# f28p65x_dev_cfg_regs register map
Vendor: Texas Instruments
Peripheral module from a debugger description file (folder C2000).
Address unit: 16 bits
Registers are 32-bit, read-write, no defined reset value unless marked. A register's access mark holds for its fields unless they carry their own. Offsets are as the file gives them; lines under a group give offsets from that group; [hi:lo] are bit positions; {n}, {i} and the like mark numbered series; 'fields as' and 'values as' point back to an identical list; <NAME> marks a mode.

## DEV_CFG_REGS — DEV CFG Registers
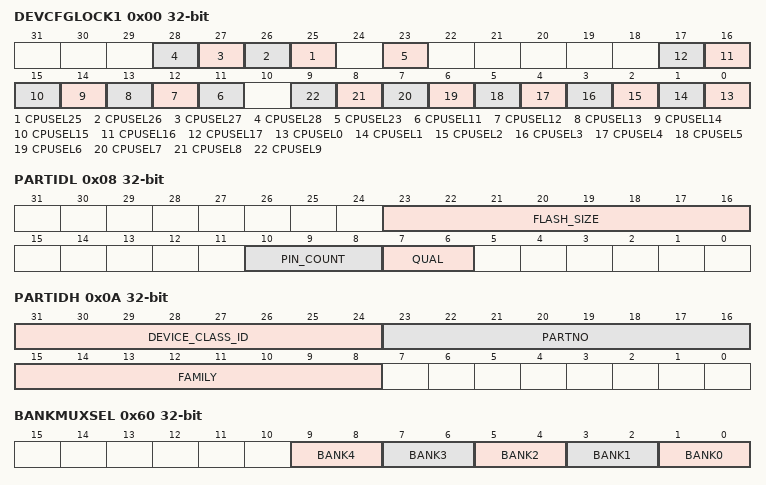
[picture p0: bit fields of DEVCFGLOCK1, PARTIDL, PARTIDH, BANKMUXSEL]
0x00 DEVCFGLOCK1 — Lock bit for CPUSELx registers
  [n] CPUSEL{n} (n=25..28) — Lock bit for CPUSEL{n} register
  [23] CPUSEL23 — Lock bit for CPUSEL23 register
  [n] CPUSEL{n} (n=11..17) — Lock bit for CPUSEL{n} register
  [n] CPUSEL{n} (n=0..9) — Lock bit for CPUSEL{n} register
0x02 DEVCFGLOCK2 — Lock bit for DEVCFG registers
  [2] BANKMUXSEL — Flash Bank Mux Select
0x08 PARTIDL — Lower 32-bit of Device PART Identification Number
  [23:16] FLASH_SIZE
  [10:8] PIN_COUNT — Device Pin Count
  [7:6] QUAL — Qualification Status
0x0A PARTIDH access per field — Upper 32-bit of Device PART Identification Number
  [31:24] DEVICE_CLASS_ID ro
  [23:16] PARTNO rw — Device part number
  [15:8] FAMILY rw — Device family
0x0C REVID — Device Revision Number
  [15:0] REVID — Device Revision ID. This is specific to the Device
0x10 DC0 access not given — Device Capability: Device Information
0x60 BANKMUXSEL — Flash Bank allocation to CPU. Internal note : This register is accessible (read-only) by CPU2, for devices with CPU2
  [2n+1:2n] BANK{n} (n=0..4) — Select Flash Bank Controller CPU for Read accesses
0x78 MCUCNF0 — MCU Configuration register for DC0.DUAL_CORE
  [0] DUAL_CORE — User Configurable Single Core vs Dual Core
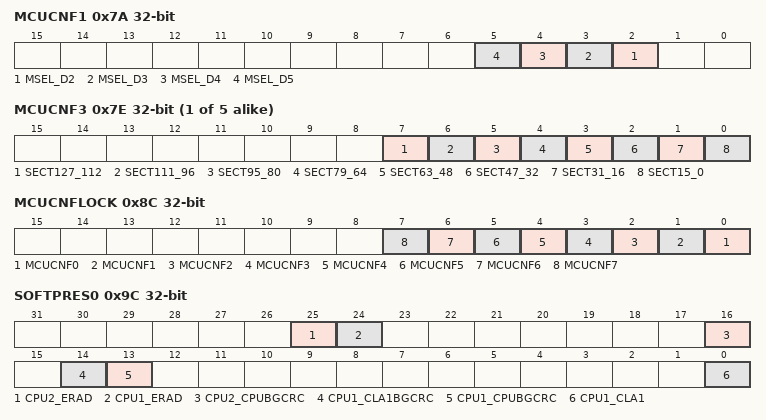
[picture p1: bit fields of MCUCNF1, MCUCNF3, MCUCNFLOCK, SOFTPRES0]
0x7A MCUCNF1 — MCU Configuration register for LockStep Feature on device
  [n] MSEL_D{n} (n=2..5) — Controller Select for MSEL_D{n}
0x7C MCUCNF2 — MCU Configuration register for EtherCAT
  [0] ETHERCAT
{0x78+2i} MCUCNF{i} (i=3..7) — MCU Configuration register for Flash Bank {i-2}
  [7] SECT127_112 — Flash sectors 127_112 present
  [6] SECT111_96 — Flash sectors 111_96 present
  [5] SECT95_80 — Flash sectors 95_80 present
  [4] SECT79_64 — Flash sectors 79_64 present
  [3] SECT63_48 — Flash sectors 63_48 present
  [2] SECT47_32 — Flash sectors 47_32 present
  [1] SECT31_16 — Flash sectors 31_16 present
  [0] SECT15_0 — Flash sectors 15_0 present
0x8C MCUCNFLOCK — Lock bit for MCUCNFx registers
  [n] MCUCNF{n} (n=0..7) — Lock bit for MCUCNF{n} register
0x8E TRIMERRSTS — TRIM Error Status register
  [15:0] LERR — TRIM Load error status
0x9C SOFTPRES0 — Processing Block Software Reset register
  [25] CPU2_ERAD — ERAD Module reset bit
  [24] CPU1_ERAD — ERAD Module reset bit
  [16] CPU2_CPUBGCRC — CPU2 CPUBGCRC Module reset bit
  [14] CPU1_CLA1BGCRC — CPU1 CLA1BGCRC Module reset bit
  [13] CPU1_CPUBGCRC — CPU1 CPUBGCRC Module reset bit
  [0] CPU1_CLA1 — CPU1_CLA1 software reset bit
0x9E SOFTPRES1 — EMIF Software Reset register
  [0] EMIF1 — EMIF1 software reset bit
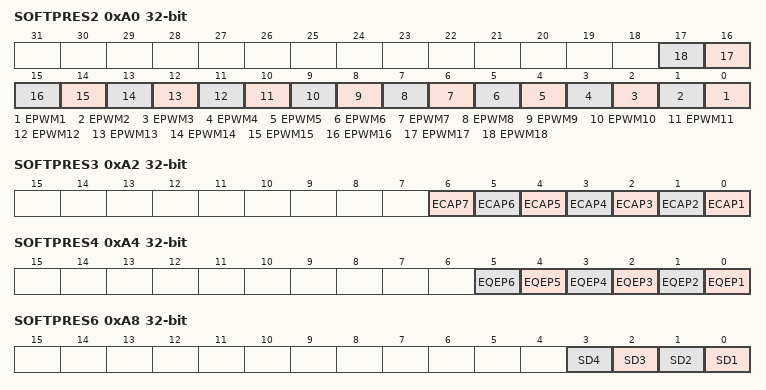
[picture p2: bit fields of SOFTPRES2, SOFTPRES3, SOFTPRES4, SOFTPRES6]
0xA0 SOFTPRES2 — EPWM Software Reset register
  [n-1] EPWM{n} (n=1..18) — EPWM{n} software reset bit
0xA2 SOFTPRES3 — ECAP Software Reset register
  [n-1] ECAP{n} (n=1..7) — ECAP{n} software reset bit
0xA4 SOFTPRES4 — EQEP Software Reset register
  [n-1] EQEP{n} (n=1..6) — EQEP{n} software reset bit
0xA8 SOFTPRES6 — Sigma Delta Software Reset register
  [n-1] SD{n} (n=1..4) — SD{n} software reset bit
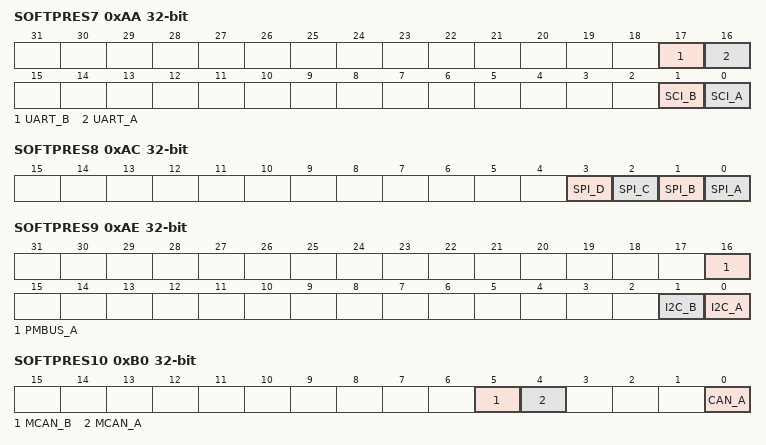
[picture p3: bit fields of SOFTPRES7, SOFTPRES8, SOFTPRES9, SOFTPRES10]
0xAA SOFTPRES7 — SCI, UART Software Reset register
  [17] UART_B — UART_B software reset bit
  [16] UART_A — UART_A software reset bit
  [1] SCI_B — SCI_B software reset bit
  [0] SCI_A — SCI_A software reset bit
0xAC SOFTPRES8 — SPI Software Reset register
  [3] SPI_D — SPI_D software reset bit
  [2] SPI_C — SPI_C software reset bit
  [1] SPI_B — SPI_B software reset bit
  [0] SPI_A — SPI_A software reset bit
0xAE SOFTPRES9 — I2C Software Reset register
  [16] PMBUS_A — PMBUS_A software reset bit
  [1] I2C_B — I2C_B software reset bit
  [0] I2C_A — I2C_A software reset bit
0xB0 SOFTPRES10 — CAN Software Reset register
  [5] MCAN_B — MCAN_B software reset bit
  [4] MCAN_A — MCAN_A software reset bit
  [0] CAN_A — CAN_A software reset bit
0xB2 SOFTPRES11 — McBSP/USB Software Reset register
  [16] USB_A — USB_A software reset bit
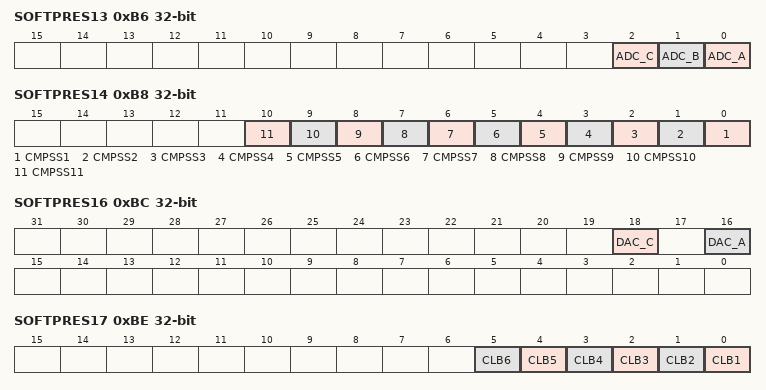
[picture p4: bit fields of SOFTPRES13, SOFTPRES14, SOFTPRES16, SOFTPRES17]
0xB6 SOFTPRES13 — ADC Software Reset register
  [2] ADC_C — ADC_C software reset bit
  [1] ADC_B — ADC_B software reset bit
  [0] ADC_A — ADC_A software reset bit
0xB8 SOFTPRES14 — CMPSS Software Reset register
  [n-1] CMPSS{n} (n=1..11) — CMPSS{n} software reset bit
0xBC SOFTPRES16 — DAC Software Reset register
  [18] DAC_C — Buffered_DAC_C software reset bit
  [16] DAC_A — Buffered_DAC_A software reset bit
0xBE SOFTPRES17 — CLB Software Reset register
  [n-1] CLB{n} (n=1..6) — CLB{n} software reset bit
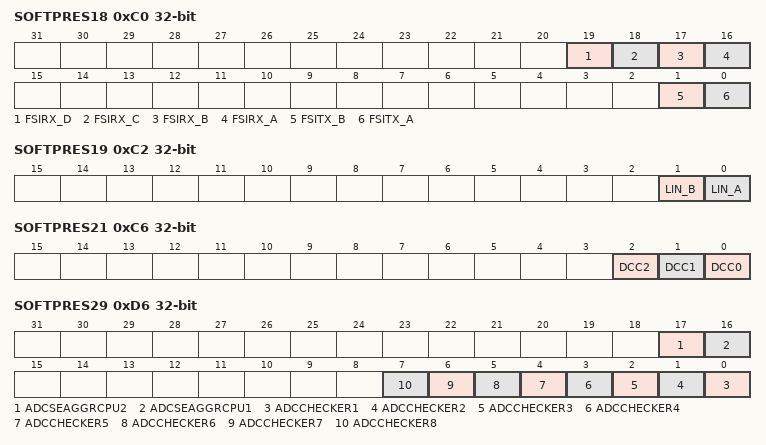
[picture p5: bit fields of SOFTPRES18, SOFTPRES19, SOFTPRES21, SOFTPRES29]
0xC0 SOFTPRES18 — FSI Software Reset register
  [19] FSIRX_D — FSIRX_D software reset bit
  [18] FSIRX_C — FSIRX_C software reset bit
  [17] FSIRX_B — FSIRX_B software reset bit
  [16] FSIRX_A — FSIRX_A software reset bit
  [1] FSITX_B — FSITX_B software reset bit
  [0] FSITX_A — FSITX_A software reset bit
0xC2 SOFTPRES19 — LIN Software Reset register
  [1] LIN_B — LIN_B software reset bit
  [0] LIN_A — LIN_A software reset bit
0xC6 SOFTPRES21 — DCC Software Reset register
  [2] DCC2 — DCC Module reset bit
  [1] DCC1 — DCC Module reset bit
  [0] DCC0 — DCC Module reset bit
0xCA SOFTPRES23 — ETHERCAT Software Reset register
  [0] ETHERCAT — ETHERCAT Module reset bit
0xD0 SOFTPRES26 — AES Software Reset register
  [0] AESA — AES Module Reset Bit
0xD2 SOFTPRES27 — EPG Software Reset register
  [0] EPG1 — EPG Module Reset Bit
0xD4 SOFTPRES28 — Flash Software Reset register
  [0] FLASHA — Flash Wrapper Module Reset Bit
0xD6 SOFTPRES29 — ADCCHECKER Software Reset register
  [17] ADCSEAGGRCPU2 — ADCSEAGGRCPU2 software reset bit
  [16] ADCSEAGGRCPU1 — ADCSEAGGRCPU1 software reset bit
  [n-1] ADCCHECKER{n} (n=1..8) — ADCCHECKER{n} software reset bit
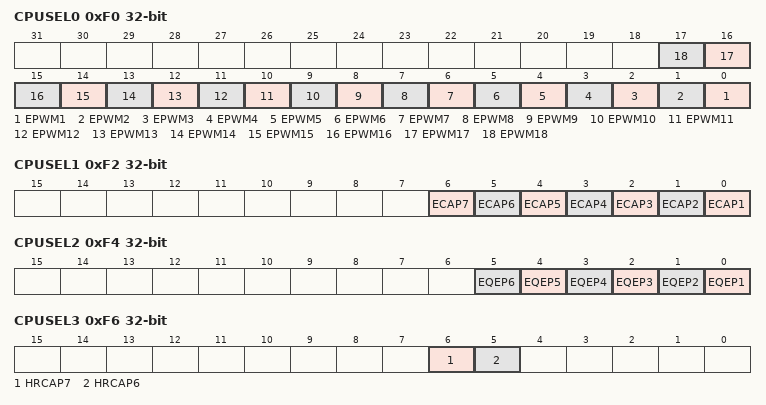
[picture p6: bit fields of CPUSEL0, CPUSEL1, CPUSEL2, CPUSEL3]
0xF0 CPUSEL0 — CPU Select register for common peripherals
  [n-1] EPWM{n} (n=1..18) — EPWM{n} CPU select bit
0xF2 CPUSEL1 — CPU Select register for common peripherals
  [n-1] ECAP{n} (n=1..7) — ECAP{n} CPU select bit
0xF4 CPUSEL2 — CPU Select register for common peripherals
  [n-1] EQEP{n} (n=1..6) — EQEP{n} CPU select bit
0xF6 CPUSEL3 — CPU Select register for common peripherals
  [6] HRCAP7 — HRCAP7 CPU select bit
  [5] HRCAP6 — HRCAP6 CPU select bit
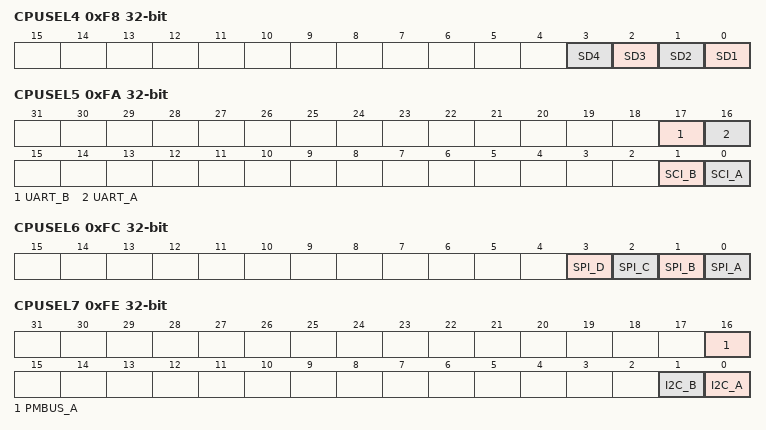
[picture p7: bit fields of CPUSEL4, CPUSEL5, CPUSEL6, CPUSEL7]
0xF8 CPUSEL4 — CPU Select register for common peripherals
  [n-1] SD{n} (n=1..4) — SD{n} CPU select bit
0xFA CPUSEL5 — CPU Select register for common peripherals
  [17] UART_B — UART_B CPU select bit
  [16] UART_A — UART_A CPU select bit
  [1] SCI_B — SCI_B CPU select bit
  [0] SCI_A — SCI_A CPU select bit
0xFC CPUSEL6 — CPU Select register for common peripherals
  [3] SPI_D — SPI_D CPU select bit
  [2] SPI_C — SPI_C CPU select bit
  [1] SPI_B — SPI_B CPU select bit
  [0] SPI_A — SPI_A CPU select bit
0xFE CPUSEL7 — CPU Select register for common peripherals
  [16] PMBUS_A — PMBUS_A CPU select bit
  [1] I2C_B — I2C_B CPU select bit
  [0] I2C_A — I2C_A CPU select bit
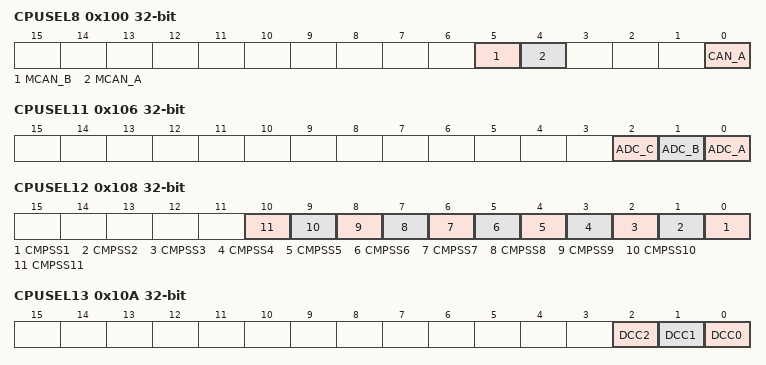
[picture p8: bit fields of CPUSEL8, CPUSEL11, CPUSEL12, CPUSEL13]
0x100 CPUSEL8 — CPU Select register for common peripherals
  [5] MCAN_B — MCAN_B CPU select bit
  [4] MCAN_A — MCAN_A CPU select bit
  [0] CAN_A — CAN_A CPU select bit
0x102 CPUSEL9 — CPU Select register for common peripherals
  [16] USB_A — USB_A CPU select bit
0x106 CPUSEL11 — CPU Select register for common peripherals
  [2] ADC_C — ADC_C CPU select bit
  [1] ADC_B — ADC_B CPU select bit
  [0] ADC_A — ADC_A CPU select bit
0x108 CPUSEL12 — CPU Select register for common peripherals
  [n-1] CMPSS{n} (n=1..11) — CMPSS{n} CPU select bit
0x10A CPUSEL13 — CPU select register for DCC
  [2] DCC2 — DCC2 CPU select bit
  [1] DCC1 — DCC1 CPU select bit
  [0] DCC0 — DCC0 CPU select bit
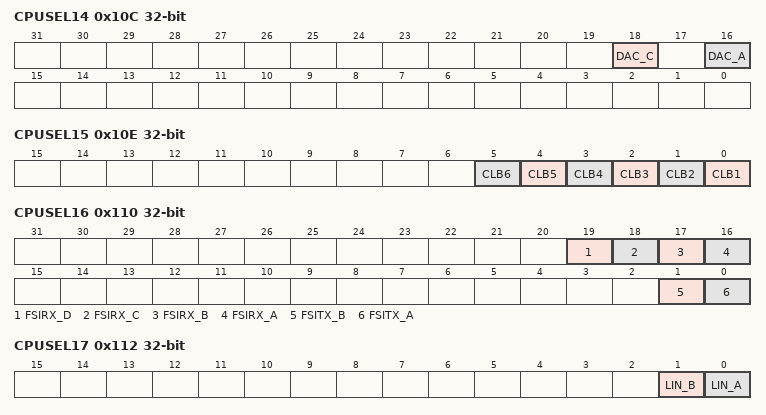
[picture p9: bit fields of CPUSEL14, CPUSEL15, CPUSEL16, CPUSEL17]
0x10C CPUSEL14 — CPU Select register for common peripherals
  [18] DAC_C — Buffered_DAC_C CPU select bit
  [16] DAC_A — Buffered_DAC_A CPU select bit
0x10E CPUSEL15 — CPU select register for CLB tiles
  [n-1] CLB{n} (n=1..6) — CLB{n} CPU select bit
0x110 CPUSEL16 — CPU select register for FSI
  [19] FSIRX_D — FSIRX_D CPU select bit
  [18] FSIRX_C — FSIRX_C CPU select bit
  [17] FSIRX_B — FSIRX_B CPU select bit
  [16] FSIRX_A — FSIRX_A CPU select bit
  [1] FSITX_B — FSITX_B CPU select bit
  [0] FSITX_A — FSITX_A CPU select bit
0x112 CPUSEL17 — CPU select register for LIN
  [1] LIN_B — LIN_B CPU select bit
  [0] LIN_A — LIN_A CPU select bit
0x11E CPUSEL23 — CPU select register for EtherCAT
  [0] ETHERCAT — 0 CPU select bit
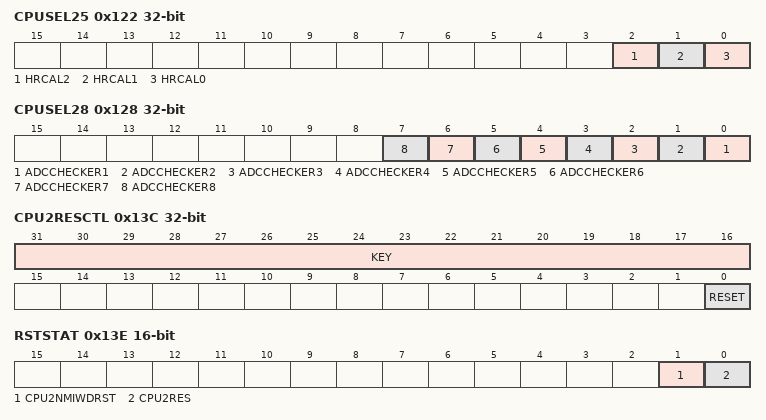
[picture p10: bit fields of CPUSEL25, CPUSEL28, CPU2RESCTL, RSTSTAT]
0x122 CPUSEL25 — CPU select register for HRCAL
  [2] HRCAL2 — HRCAL2 CPU select bit
  [1] HRCAL1 — HRCAL1 CPU select bit
  [0] HRCAL0 — HRCAL0 CPU select bit
0x124 CPUSEL26 — CPU select register for AES
  [0] AESA — AESA CPU select bit
0x126 CPUSEL27 — CPU select register for EPG
  [0] EPG1 — EPG1 CPU select bit
0x128 CPUSEL28 — CPU select register for ADCCHECKER tiles
  [n-1] ADCCHECKER{n} (n=1..8) — ADCCHECKER{n} CPU select bit
0x13C CPU2RESCTL — CPU2 Reset Control Register
  [31:16] KEY — Key Qualifier for writes to this register
  [0] RESET — CPU2 Reset Control bit
0x13E RSTSTAT 16-bit access per field — Reset Status register for secondary C28x CPUs
  [1] CPU2NMIWDRST rw — Indicates whether a CPU2.NMIWD reset was issued to CPU2
  [0] CPU2RES ro — CPU2 Reset Status bit
0x13F LPMSTAT 16-bit ro — LPM Status Register for secondary C28x CPUs
  [1:0] CPU2LPMSTAT — CPU2 LPM Status
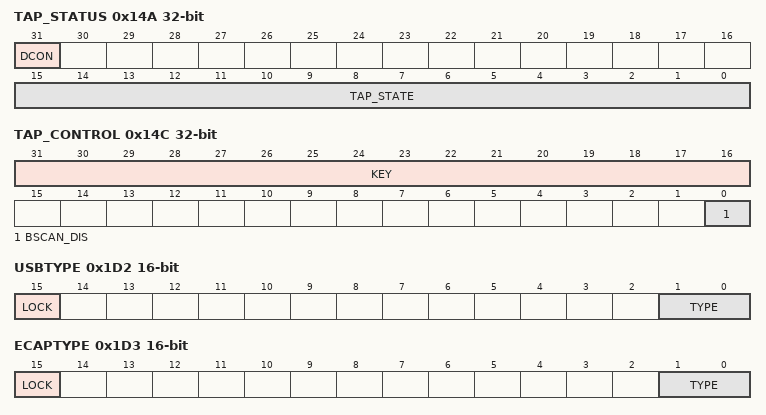
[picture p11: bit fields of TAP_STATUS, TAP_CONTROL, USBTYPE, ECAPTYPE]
0x14A TAP_STATUS ro — Status of JTAG State machine and Debugger Connect
  [31] DCON — Debugger Connect Indication
  [15:0] TAP_STATE — Present TAP State
0x14C TAP_CONTROL — Disable TAP control
  [31:16] KEY — Key value to enable write
  [0] BSCAN_DIS — Disable BSCAN TAP control
0x1D2 USBTYPE 16-bit — Configures USB Type for the device
  [15] LOCK — Lock bit
  [1:0] TYPE — Configure USB type
0x1D3 ECAPTYPE 16-bit — Configures ECAP Type for the device
  [15] LOCK — Lock bit for the register
  [1:0] TYPE — Configure ECAP type
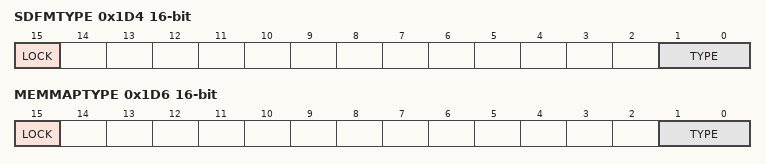
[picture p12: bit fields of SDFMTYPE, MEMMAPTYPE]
0x1D4 SDFMTYPE 16-bit — Configures SDFM Type for the device
  [15] LOCK — Lock bit
  [1:0] TYPE — Configure SDFM type
0x1D6 MEMMAPTYPE 16-bit — Configures Memory Map Type for the device
  [15] LOCK — Lock bit
  [1:0] TYPE — Configures system specific features related to memory map.
